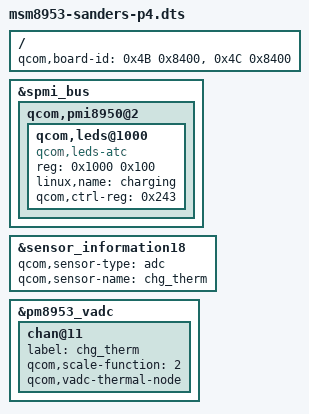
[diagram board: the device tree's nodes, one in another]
/* Copyright (c) 2015, Motorola Mobility Inc. All rights reserved.
 *
 * This program is free software; you can redistribute it and/or modify
 * it under the terms of the GNU General Public License version 2 and
 * only version 2 as published by the Free Software Foundation.
 *
 * This program is distributed in the hope that it will be useful,
 * but WITHOUT ANY WARRANTY; without even the implied warranty of
 * MERCHANTABILITY or FITNESS FOR A PARTICULAR PURPOSE.  See the
 * GNU General Public License for more details.
 */

/dts-v1/;


#include "msm8953-sanders.dtsi"


/ {
	qcom,board-id = <0x4B 0x8400>,<0x4C 0x8400>;
};

&spmi_bus {
	qcom,pmi8950@2 {
		/delete-node/ qcom,leds@a100;
		qcom,leds@1000 {
			status = "okay";
			reg = <0x1000 0x100>;
			compatible = "qcom,leds-atc";
			linux,name = "charging";
			qcom,ctrl-reg = <0x243>;
		};
	};
};

&sensor_information18 {
	qcom,sensor-type = "adc";
	qcom,sensor-name = "chg_therm";
};

&pm8953_vadc {
	chan@11 {
		label = "chg_therm";
		qcom,scale-function = <2>;
		qcom,vadc-thermal-node;
	};
};
